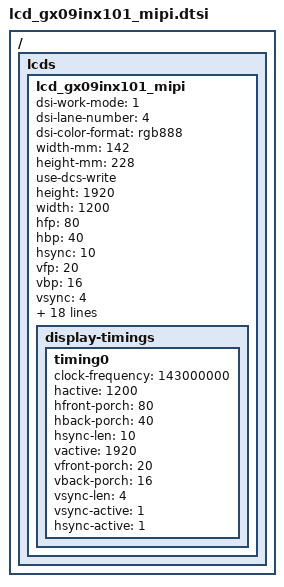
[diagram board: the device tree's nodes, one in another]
// SPDX-License-Identifier: GPL-2.0

/ { lcds: lcds {
	lcd_gx09inx101_mipi: lcd_gx09inx101_mipi {
		dsi-work-mode = <1>; /* video burst mode*/
		dsi-lane-number = <4>;
		dsi-color-format = "rgb888";
		width-mm = <142>;
		height-mm = <228>;
		use-dcs-write;

		/*mipi info*/
		height = <1920>;
		width = <1200>;
		hfp = <80>;
		hbp = <40>;
		hsync = <10>;
		vfp = <20>;
		vbp = <16>;
		vsync = <4>;
		fps = <60>;
		work-mode = <0>;
		rgb-mode = <3>;
		lane-number = <4>;
		phy-bit-clock = <1000000000>;
		phy-esc-clock = <76800000>;
		split-enable = <0>;
		eotp-enable = <0>;
		burst-mode = <2>;
		esd-check-enable = <0>;

		/* DSI_CMD, DSI_MODE, timeout, len, cmd */
		initial-command = [
			39 01 00 02 B0 01
			39 01 00 02 C3 4F
			39 01 00 02 C4 40
			39 01 00 02 C5 40
			39 01 00 02 C6 40
			39 01 00 02 C7 40
			39 01 00 02 C8 4D
			39 01 00 02 C9 52
			39 01 00 02 CA 51
			39 01 00 02 CD 5D
			39 01 00 02 CE 5B
			39 01 00 02 CF 4B
			39 01 00 02 D0 49
			39 01 00 02 D1 47
			39 01 00 02 D2 45
			39 01 00 02 D3 41
			39 01 00 02 D7 50
			39 01 00 02 D8 40
			39 01 00 02 D9 40
			39 01 00 02 DA 40
			39 01 00 02 DB 40
			39 01 00 02 DC 4E
			39 01 00 02 DD 52
			39 01 00 02 DE 51
			39 01 00 02 E1 5E
			39 01 00 02 E2 5C
			39 01 00 02 E3 4C
			39 01 00 02 E4 4A
			39 01 00 02 E5 48
			39 01 00 02 E6 46
			39 01 00 02 E7 42
			39 01 00 02 B0 03
			39 01 00 02 BE 03
			39 01 00 02 CC 44
			39 01 00 02 C8 07
			39 01 00 02 C9 05
			39 01 00 02 CA 42
			39 01 00 02 CD 3E
			39 01 00 02 CF 60
			39 01 00 02 D2 04
			39 01 00 02 D3 04
			39 01 00 02 D4 01
			39 01 00 02 D5 00
			39 01 00 02 D6 03
			39 01 00 02 D7 04
			39 01 00 02 D9 01
			39 01 00 02 DB 01
			39 01 00 02 E4 F0
			39 01 00 02 E5 0A
			39 01 00 02 B0 00
			39 01 00 02 BD 50
			39 01 00 02 C2 08
			39 01 00 02 C4 10
			39 01 00 02 CC 00
			// 39 01 00 02 B2 41 // BIST pattern
			39 01 00 02 B0 02
			39 01 00 02 C0 00
			39 01 00 02 C1 0A
			39 01 00 02 C2 20
			39 01 00 02 C3 24
			39 01 00 02 C4 23
			39 01 00 02 C5 29
			39 01 00 02 C6 23
			39 01 00 02 C7 1C
			39 01 00 02 C8 19
			39 01 00 02 C9 17
			39 01 00 02 CA 17
			39 01 00 02 CB 18
			39 01 00 02 CC 1A
			39 01 00 02 CD 1E
			39 01 00 02 CE 20
			39 01 00 02 CF 23
			39 01 00 02 D0 07
			39 01 00 02 D1 00
			39 01 00 02 D2 00
			39 01 00 02 D3 0A
			39 01 00 02 D4 13
			39 01 00 02 D5 1C
			39 01 00 02 D6 1A
			39 01 00 02 D7 13
			39 01 00 02 D8 17
			39 01 00 02 D9 1C
			39 01 00 02 DA 19
			39 01 00 02 DB 17
			39 01 00 02 DC 17
			39 01 00 02 DD 18
			39 01 00 02 DE 1A
			39 01 00 02 DF 1E
			39 01 00 02 E0 20
			39 01 00 02 E1 23
			39 01 00 02 E2 07
			39 01 F0 01 11
			39 01 28 01 29
		];
		sleep-in-command = [
			39 01 78 01 28
			39 01 78 01 10
		];
		sleep-out-command = [
			39 01 96 01 11
			39 01 32 01 29
		];
		read-id-command = [
			37 01 00 01 05
			14 01 00 05 fb fc fd fe ff
		];

		display-timings {
			timing0 {
				clock-frequency = <143000000>;
				hactive = <1200>;
				hfront-porch = <80>;
				hback-porch = <40>;
				hsync-len = <10>;
				vactive = <1920>;
				vfront-porch = <20>;
				vback-porch = <16>;
				vsync-len = <4>;
				vsync-active = <1>;
				hsync-active = <1>;
			};
		};
	};
};};
